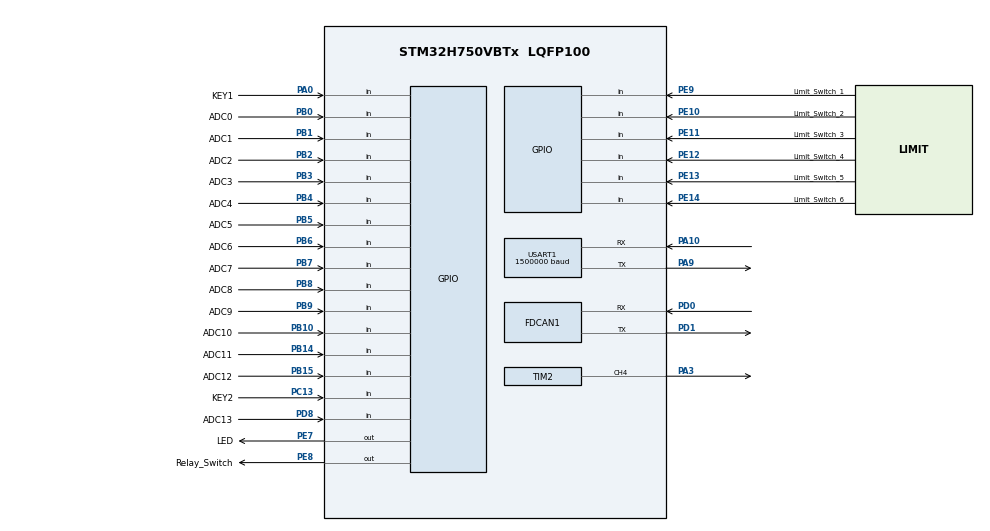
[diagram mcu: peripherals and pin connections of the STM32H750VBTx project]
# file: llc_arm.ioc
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CORTEX_M7.default_mode_Activation=1
FDCAN1.AutoRetransmission=ENABLE
FDCAN1.CalculateBaudRateNominal=1000000
FDCAN1.CalculateTimeBitNominal=1000
FDCAN1.CalculateTimeQuantumNominal=12.5
FDCAN1.DataSyncJumpWidth=4
FDCAN1.DataTimeSeg1=11
FDCAN1.DataTimeSeg2=4
FDCAN1.FrameFormat=FDCAN_FRAME_FD_BRS
FDCAN1.NominalPrescaler=1
FDCAN1.NominalSyncJumpWidth=20
FDCAN1.NominalTimeSeg1=59
FDCAN1.NominalTimeSeg2=20
FDCAN1.ProtocolException=ENABLE
FDCAN1.RxFifo0ElmtSize=FDCAN_DATA_BYTES_32
FDCAN1.RxFifo0ElmtsNbr=32
FDCAN1.RxFifo1ElmtSize=FDCAN_DATA_BYTES_32
FDCAN1.RxFifo1ElmtsNbr=8
FDCAN1.StdFiltersNbr=32
FDCAN1.TxElmtSize=FDCAN_DATA_BYTES_20
FDCAN1.TxFifoQueueElmtsNbr=32
FREERTOS.Tasks01=Led,24,128,Led_start,As weak,NULL,Dynamic,NULL,NULL;Motor_Control,48,256,Motor_Control_start,As weak,NULL,Dynamic,NULL,NULL
FREERTOS.configENABLE_FPU=1
FREERTOS.configIDLE_SHOULD_YIELD=1
FREERTOS.configLIBRARY_MAX_SYSCALL_INTERRUPT_PRIORITY=1
Mcu.Family=STM32H7
Mcu.Name=STM32H750VBTx
Mcu.Package=LQFP100
NVIC.FDCAN1_IT0_IRQn=true\:1\:0\:true\:false\:true\:true\:true\:true\:true
NVIC.FDCAN1_IT1_IRQn=true\:1\:0\:true\:false\:true\:true\:true\:true\:true
NVIC.PriorityGroup=NVIC_PRIORITYGROUP_4
NVIC.TIM1_UP_IRQn=true\:0\:0\:true\:false\:true\:false\:false\:true\:true
NVIC.TimeBase=TIM1_UP_IRQn
NVIC.TimeBaseIP=TIM1
NVIC.USART1_IRQn=true\:1\:0\:false\:false\:true\:true\:true\:true\:true
PA0.GPIO_Label=KEY1
PA0.GPIO_PuPd=GPIO_PULLDOWN
PA0.Signal=GPIO_Input
PA10.Mode=Asynchronous
PA10.Signal=USART1_RX
PA13\ (JTMS/SWDIO).Mode=Serial_Wire
PA13\ (JTMS/SWDIO).Signal=DEBUG_JTMS-SWDIO
PA14\ (JTCK/SWCLK).Mode=Serial_Wire
PA14\ (JTCK/SWCLK).Signal=DEBUG_JTCK-SWCLK
PA3.GPIO_Speed=GPIO_SPEED_FREQ_VERY_HIGH
PA3.Signal=S_TIM2_CH4
PA9.Mode=Asynchronous
PA9.Signal=USART1_TX
PB0.GPIO_Label=ADC0
PB0.Signal=GPIO_Input
PB1.GPIO_Label=ADC1
PB1.Signal=GPIO_Input
PB10.GPIO_Label=ADC10
PB10.Signal=GPIO_Input
PB14.GPIO_Label=ADC11
PB14.Signal=GPIO_Input
PB15.GPIO_Label=ADC12
PB15.Signal=GPIO_Input
PB2.GPIO_Label=ADC2
PB2.Signal=GPIO_Input
PB3\ (JTDO/TRACESWO).GPIO_Label=ADC3
PB3\ (JTDO/TRACESWO).Signal=GPIO_Input
PB4\ (NJTRST).GPIO_Label=ADC4
PB4\ (NJTRST).Signal=GPIO_Input
PB5.GPIO_Label=ADC5
PB5.Signal=GPIO_Input
PB6.GPIO_Label=ADC6
PB6.Signal=GPIO_Input
PB7.GPIO_Label=ADC7
PB7.Signal=GPIO_Input
PB8.GPIO_Label=ADC8
PB8.Signal=GPIO_Input
PB9.GPIO_Label=ADC9
PB9.Signal=GPIO_Input
PC13.GPIO_Label=KEY2
PC13.GPIO_PuPd=GPIO_PULLDOWN
PC13.Signal=GPIO_Input
PD0.GPIO_Speed=GPIO_SPEED_FREQ_HIGH
PD0.Mode=FDCAN_Activate
PD0.Signal=FDCAN1_RX
PD1.GPIO_Speed=GPIO_SPEED_FREQ_HIGH
PD1.Mode=FDCAN_Activate
PD1.Signal=FDCAN1_TX
PD8.GPIO_Label=ADC13
PD8.Signal=GPIO_Input
PE10.GPIO_Label=Limit_Switch_2
PE10.GPIO_PuPd=GPIO_PULLUP
PE10.Signal=GPIO_Input
PE11.GPIO_Label=Limit_Switch_3
PE11.GPIO_PuPd=GPIO_PULLUP
PE11.Signal=GPIO_Input
PE12.GPIO_Label=Limit_Switch_4
PE12.GPIO_PuPd=GPIO_PULLUP
PE12.Signal=GPIO_Input
PE13.GPIO_Label=Limit_Switch_5
PE13.GPIO_PuPd=GPIO_PULLUP
PE13.Signal=GPIO_Input
PE14.GPIO_Label=Limit_Switch_6
PE14.GPIO_PuPd=GPIO_PULLUP
PE14.Signal=GPIO_Input
PE7.GPIO_Label=LED
PE7.Signal=GPIO_Output
PE8.GPIO_Label=Relay_Switch 
PE8.GPIO_Speed=GPIO_SPEED_FREQ_HIGH
PE8.Signal=GPIO_Output
PE9.GPIO_Label=Limit_Switch_1
PE9.GPIO_PuPd=GPIO_PULLUP
PE9.Signal=GPIO_Input
PH0-OSC_IN\ (PH0).Mode=HSE-External-Oscillator
PH0-OSC_IN\ (PH0).Signal=RCC_OSC_IN
PH1-OSC_OUT\ (PH1).Mode=HSE-External-Oscillator
PH1-OSC_OUT\ (PH1).Signal=RCC_OSC_OUT
ProjectManager.HeapSize=0x200
ProjectManager.StackSize=0x400
ProjectManager.TargetToolchain=MDK-ARM V5.32
RCC.ADCFreq_Value=80000000
RCC.APB1Freq_Value=100000000
RCC.APB2Freq_Value=100000000
RCC.APB3Freq_Value=100000000
RCC.APB4Freq_Value=100000000
RCC.CortexFreq_Value=400000000
RCC.D1PPRE=RCC_APB3_DIV2
RCC.D2PPRE1=RCC_APB1_DIV2
RCC.D2PPRE2=RCC_APB2_DIV2
RCC.D3PPRE=RCC_APB4_DIV2
RCC.DIVM1=2
RCC.DIVM2=25
RCC.DIVM3=25
RCC.DIVN1=64
RCC.DIVN2=160
RCC.DIVN3=270
RCC.FDCANCLockSelection=RCC_FDCANCLKSOURCE_PLL2
RCC.HCLKFreq_Value=200000000
RCC.HPRE=RCC_HCLK_DIV2
RCC.PLLFRACN=0
RCC.PLLSourceVirtual=RCC_PLLSOURCE_HSE
RCC.PWR_Regulator_Voltage_Scale=PWR_REGULATOR_VOLTAGE_SCALE0
RCC.SYSCLKFreq_VALUE=400000000
RCC.SYSCLKSource=RCC_SYSCLKSOURCE_PLLCLK
RCC.USBFreq_Value=400000000
SH.S_TIM2_CH4.0=TIM2_CH4,PWM Generation4 CH4
STMicroelectronics.X-CUBE-ALGOBUILD.1.4.0.LibraryCcDSPOoLibraryJjDSPOoLibrary=true
TIM2.AutoReloadPreload=TIM_AUTORELOAD_PRELOAD_ENABLE
TIM2.Channel-PWM\ Generation4\ CH4=TIM_CHANNEL_4
TIM2.Period=199
TIM2.Prescaler=0
TIM2.Pulse-PWM\ Generation4\ CH4=100
USART1.BaudRate=1500000
USART1.VirtualMode-Asynchronous=VM_ASYNC
VP_FREERTOS_VS_CMSIS_V2.Mode=CMSIS_V2
VP_MEMORYMAP_VS_MEMORYMAP.Mode=CurAppReg
VP_STMicroelectronics.X-CUBE-ALGOBUILD_VS_DSPOoLibraryJjLibrary_1.4.0_1.4.0.Mode=DSPOoLibraryJjLibrary
VP_SYS_VS_tim1.Mode=TIM1
VP_TIM2_VS_ClockSourceINT.Mode=Internal
board=custom

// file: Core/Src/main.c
/* USER CODE BEGIN Header */
/**
  ******************************************************************************
  * @file           : main.c
  * @brief          : Main program body
  ******************************************************************************
  * @attention
  *
  * Copyright (c) 2025 STMicroelectronics.
  * All rights reserved.
  *
  * This software is licensed under terms that can be found in the LICENSE file
  * in the root directory of this software component.
  * If no LICENSE file comes with this software, it is provided AS-IS.
  *
  ******************************************************************************
  */
/* USER CODE END Header */
#include "main.h"
#include "cmsis_os.h"
#include "fdcan.h"
#include "memorymap.h"
#include "tim.h"
#include "usart.h"
#include "gpio.h"

/* USER CODE BEGIN Includes */

#include "fdcan_fliter.h"
#include "arm_math.h"

/* USER CODE END Includes */

void SystemClock_Config(void);
static void MPU_Config(void);
void MX_FREERTOS_Init(void);

/* USER CODE BEGIN 0 */
//串口重定义
int fputc(int ch,FILE *f)
{
    HAL_UART_Transmit(&huart1,(uint8_t *)&ch,1,100);
    return 0;
}
/* USER CODE END 0 */

int main(void)
{

  /* MPU Configuration--------------------------------------------------------*/
  MPU_Config();

  /* MCU Configuration--------------------------------------------------------*/

  /* Reset of all peripherals, Initializes the Flash interface and the Systick. */
  HAL_Init();

  /* Configure the system clock */
  SystemClock_Config();

  /* Initialize all configured peripherals */
  MX_GPIO_Init();
  MX_FDCAN1_Init();
  MX_TIM2_Init();
  MX_USART1_UART_Init();
  /* USER CODE BEGIN 2 */
	FDCAN_Filter_Config();
	HAL_TIM_PWM_Start(&htim2, TIM_CHANNEL_4);
  /* USER CODE END 2 */

  /* Init scheduler */
  osKernelInitialize();

  /* Call init function for freertos objects (in cmsis_os2.c) */
  MX_FREERTOS_Init();

  /* Start scheduler */
  osKernelStart();

  /* We should never get here as control is now taken by the scheduler */

  /* Infinite loop */
  while (1)
  {

  }
}

void SystemClock_Config(void)
{
  RCC_OscInitTypeDef RCC_OscInitStruct = {0};
  RCC_ClkInitTypeDef RCC_ClkInitStruct = {0};

  /** Supply configuration update enable
  */
  HAL_PWREx_ConfigSupply(PWR_LDO_SUPPLY);

  /** Configure the main internal regulator output voltage
  */
  __HAL_PWR_VOLTAGESCALING_CONFIG(PWR_REGULATOR_VOLTAGE_SCALE1);

  while(!__HAL_PWR_GET_FLAG(PWR_FLAG_VOSRDY)) {}

  __HAL_RCC_SYSCFG_CLK_ENABLE();
  __HAL_PWR_VOLTAGESCALING_CONFIG(PWR_REGULATOR_VOLTAGE_SCALE0);

  while(!__HAL_PWR_GET_FLAG(PWR_FLAG_VOSRDY)) {}

  /** Initializes the RCC Oscillators according to the specified parameters
  * in the RCC_OscInitTypeDef structure.
  */
  RCC_OscInitStruct.OscillatorType = RCC_OSCILLATORTYPE_HSE;
  RCC_OscInitStruct.HSEState = RCC_HSE_ON;
  RCC_OscInitStruct.PLL.PLLState = RCC_PLL_ON;
  RCC_OscInitStruct.PLL.PLLSource = RCC_PLLSOURCE_HSE;
  RCC_OscInitStruct.PLL.PLLM = 2;
  RCC_OscInitStruct.PLL.PLLN = 64;
  RCC_OscInitStruct.PLL.PLLP = 2;
  RCC_OscInitStruct.PLL.PLLQ = 2;
  RCC_OscInitStruct.PLL.PLLR = 2;
  RCC_OscInitStruct.PLL.PLLRGE = RCC_PLL1VCIRANGE_3;
  RCC_OscInitStruct.PLL.PLLVCOSEL = RCC_PLL1VCOWIDE;
  RCC_OscInitStruct.PLL.PLLFRACN = 0;
  if (HAL_RCC_OscConfig(&RCC_OscInitStruct) != HAL_OK)
  {
    Error_Handler();
  }

  /** Initializes the CPU, AHB and APB buses clocks
  */
  RCC_ClkInitStruct.ClockType = RCC_CLOCKTYPE_HCLK|RCC_CLOCKTYPE_SYSCLK
                              |RCC_CLOCKTYPE_PCLK1|RCC_CLOCKTYPE_PCLK2
                              |RCC_CLOCKTYPE_D3PCLK1|RCC_CLOCKTYPE_D1PCLK1;
  RCC_ClkInitStruct.SYSCLKSource = RCC_SYSCLKSOURCE_PLLCLK;
  RCC_ClkInitStruct.SYSCLKDivider = RCC_SYSCLK_DIV1;
  RCC_ClkInitStruct.AHBCLKDivider = RCC_HCLK_DIV2;
  RCC_ClkInitStruct.APB3CLKDivider = RCC_APB3_DIV2;
  RCC_ClkInitStruct.APB1CLKDivider = RCC_APB1_DIV2;
  RCC_ClkInitStruct.APB2CLKDivider = RCC_APB2_DIV2;
  RCC_ClkInitStruct.APB4CLKDivider = RCC_APB4_DIV2;

  if (HAL_RCC_ClockConfig(&RCC_ClkInitStruct, FLASH_LATENCY_2) != HAL_OK)
  {
    Error_Handler();
  }
}

 /* MPU Configuration */

void MPU_Config(void)
{
  MPU_Region_InitTypeDef MPU_InitStruct = {0};

  /* Disables the MPU */
  HAL_MPU_Disable();

  /** Initializes and configures the Region and the memory to be protected
  */
  MPU_InitStruct.Enable = MPU_REGION_ENABLE;
  MPU_InitStruct.Number = MPU_REGION_NUMBER0;
  MPU_InitStruct.BaseAddress = 0x0;
  MPU_InitStruct.Size = MPU_REGION_SIZE_4GB;
  MPU_InitStruct.SubRegionDisable = 0x87;
  MPU_InitStruct.TypeExtField = MPU_TEX_LEVEL0;
  MPU_InitStruct.AccessPermission = MPU_REGION_NO_ACCESS;
  MPU_InitStruct.DisableExec = MPU_INSTRUCTION_ACCESS_DISABLE;
  MPU_InitStruct.IsShareable = MPU_ACCESS_SHAREABLE;
  MPU_InitStruct.IsCacheable = MPU_ACCESS_NOT_CACHEABLE;
  MPU_InitStruct.IsBufferable = MPU_ACCESS_NOT_BUFFERABLE;

  HAL_MPU_ConfigRegion(&MPU_InitStruct);
  /* Enables the MPU */
  HAL_MPU_Enable(MPU_PRIVILEGED_DEFAULT);

}

void HAL_TIM_PeriodElapsedCallback(TIM_HandleTypeDef *htim)
{
  if (htim->Instance == TIM1) {
    HAL_IncTick();
  }
}

void Error_Handler(void)
{
  __disable_irq();
  while (1)
  {
  }
}

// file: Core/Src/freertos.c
/* USER CODE BEGIN Header */
/**
  ******************************************************************************
  * File Name          : freertos.c
  * Description        : Code for freertos applications
  ******************************************************************************
  * @attention
  *
  * Copyright (c) 2025 STMicroelectronics.
  * All rights reserved.
  *
  * This software is licensed under terms that can be found in the LICENSE file
  * in the root directory of this software component.
  * If no LICENSE file comes with this software, it is provided AS-IS.
  *
  ******************************************************************************
  */
/* USER CODE END Header */

#include "FreeRTOS.h"
#include "task.h"
#include "main.h"
#include "cmsis_os.h"

/* Definitions for Led */
osThreadId_t LedHandle;
const osThreadAttr_t Led_attributes = {
  .name = "Led",
  .stack_size = 128 * 4,
  .priority = (osPriority_t) osPriorityNormal,
};
/* Definitions for Motor_Control */
osThreadId_t Motor_ControlHandle;
const osThreadAttr_t Motor_Control_attributes = {
  .name = "Motor_Control",
  .stack_size = 256 * 4,
  .priority = (osPriority_t) osPriorityRealtime,
};

void Led_start(void *argument);
void Motor_Control_start(void *argument);

void MX_FREERTOS_Init(void); /* (MISRA C 2004 rule 8.1) */

void MX_FREERTOS_Init(void) {

  /* Create the thread(s) */
  /* creation of Led */
  LedHandle = osThreadNew(Led_start, NULL, &Led_attributes);

  /* creation of Motor_Control */
  Motor_ControlHandle = osThreadNew(Motor_Control_start, NULL, &Motor_Control_attributes);

}

__weak void Led_start(void *argument)
{
  for(;;)
  {
    osDelay(1);
  }
}

__weak void Motor_Control_start(void *argument)
{
  for(;;)
  {
    osDelay(1);
  }
}
